# RSL15 register map
Vendor: ONSemiconductor; Series: RSL15 Series; File version: 1.0
onsemi RSL15
CPU: CM33 r0p4, little endian, MPU, FPU, 3 interrupt priority bits
Registers are 32-bit, read-write, reset 0x0 unless marked. A register's access mark holds for its fields unless they carry their own. Offsets are from the block's base; lines under a group give offsets from that group; [hi:lo] are bit positions; {n}, {i} and the like mark numbered series; 'fields as' and 'values as' point back to an identical list; <NAME> marks a mode.

## Memory map
0x1FFFFFFC AHBREGS size 0x4 — AHB registers
0x40000000 SYSCTRL size 0x100 — System Control
0x40000100 CLK size 0x10 — Clock Generation
0x40000200 RESET size 0x4
0x40000300 WATCHDOG size 0x100 — Watchdog Timer
0x40000400 TIMER0 size 0x100 — General-Purpose Timers
0x40000500 TIMER1 size 0x100 — General-Purpose Timers
0x40000600 TIMER2 size 0x100 — General-Purpose Timers
0x40000700 TIMER3 size 0x100 — General-Purpose Timers
0x40000800 FLASH size 0x100 — Flash Interface
0x40000900 GPIO size 0x158 — GPIO Interface and Digital Pad control
0x40000B00 SPI0 size 0x100 — SPI Interface
0x40000C00 SPI1 size 0x100 — SPI Interface
0x40000D00 I2C0 size 0x100 — I2C Interface
0x40000E00 I2C1 size 0x100 — I2C Interface
0x40000F00 UART size 0x100 — UART Interface
0x40001000 PCM size 0x100 — PCM Interface
0x40001100 PWM size 0x100 — PWM Interface
0x40001200 DMA0 size 0x100 — DMA Controller
0x40001300 DMA1 size 0x100 — DMA Controller
0x40001400 DMA2 size 0x100 — DMA Controller
0x40001500 DMA3 size 0x100 — DMA Controller
0x40001600 CRC size 0x100 — CRC Generator Control
0x40001700 ASCC size 0x100
0x40001800 BBIF size 0x100 — Baseband Controller Interface
0x40001900 BB size 0x18C — Baseband Controller
0x40001B00 ACS size 0xA0
0x40001C00 LSAD size 0x100
0x40001D00 SENSOR size 0x74 — Sensor Interface
0x40001E00 TOF size 0x100 — Time Of Flight Timer
0x40002000 LIN size 0x100 — LIN Interface
0x40040800 RF0 size 0x200 — RF Front-End 2.4 GHz
0x40040A00 RF1 size 0x200 — RF Front-End 2.4 GHz
0x40040C00 RF2 size 0x200 — RF Front-End 2.4 GHz
0xE000E004 ICB size 0x4 — Implementation Control Block
0xE000E010 SysTick size 0x10 — SysTick Timer
0xE000E100 NVIC size 0x2043C — Nested Vector Interrupt Controller
0xE000ED00 SCB size 0x90 — System Control Block
0xE000ED90 MPU size 0x34 — Memory Protection Unit
0xE000EDD0 SAU size 0x1C — Security Attribution Unit
0xE000EDF0 DEBUG size 0x1C — Debug Control Block
0xE000EF00 SIG size 0x4 — Software Interrupt Generation
0xE000EF34 FPE size 0x18 — Floating-Point Extension

## AHBREGS — AHB registers
Base 0x1FFFFFFC
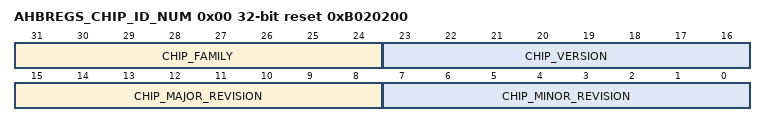
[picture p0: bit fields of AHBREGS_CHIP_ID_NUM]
0x00 AHBREGS_CHIP_ID_NUM ro reset 0xB020200 — Chip ID number
  [31:24] CHIP_FAMILY — Chip Family number
    11=CHIP_FAMILY_NB (BLE family)
  [23:16] CHIP_VERSION — Chip Version number
    2=CHIP_VERSION_NB (Value for Nechako)
  [15:8] CHIP_MAJOR_REVISION — Chip Major Revision number
    2=CHIP_MAJOR_REVISION_NB (Value for Nechako SV2)
  [7:0] CHIP_MINOR_REVISION — Chip Minor Revision number
    0=CHIP_MINOR_REVISION_NB (Value for Nechako SV2)

## CLK — Clock Generation
Base 0x40000100
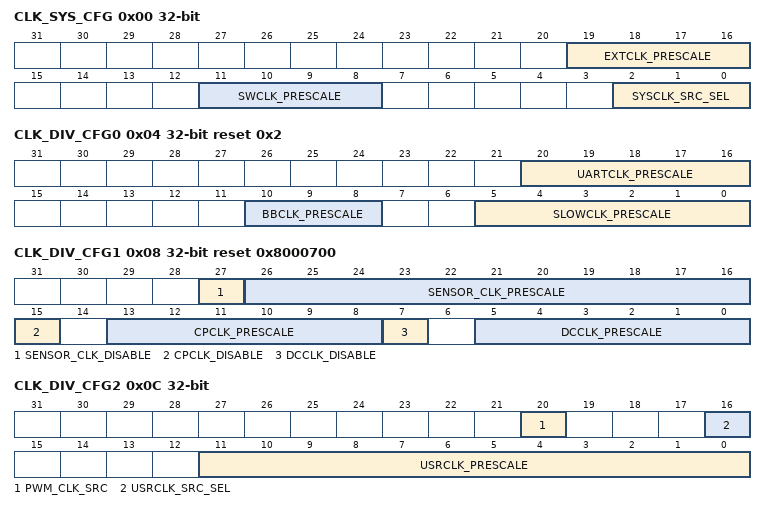
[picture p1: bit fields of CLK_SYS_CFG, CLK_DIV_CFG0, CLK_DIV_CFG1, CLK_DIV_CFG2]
0x00 CLK_SYS_CFG — System Clock Configuration Register
  [19:16] EXTCLK_PRESCALE — Prescale value for the input clock EXTCLK (1 to 16 in steps of 1)
    0=Divide by 1; 1=Divide by 2; 3=Divide by 4; 7=Divide by 8; 14=Divide by 15; 15=Divide by 16
  [11:8] SWCLK_PRESCALE — Prescale value for the input clock from pad SWCLK (1 to 16 in steps of 1)
    values as EXTCLK_PRESCALE
  [2:0] SYSCLK_SRC_SEL — Controls the source of the system clock : SWCLK, RFCLK, RCCLK, or STANDBYCLK
    0=SYSCLK_CLKSRC_RCCLK (Select the RCCLK clock as SYSCLK clock source); 1=SYSCLK_CLKSRC_STANDBYCLK (Select the STANDBYCLK clock as SYSCLK clock source); 2=SYSCLK_CLKSRC_RFCLK (Select the RFCLK clock as SYSCLK clock source); 3=SYSCLK_CLKSRC_SWCLK (Select the SWCLK clock as SYSCLK clock source); 4=SYSCLK_CLKSRC_EXTCLK (Select the EXTCLK clock asSYSCLK clock source)
0x04 CLK_DIV_CFG0 reset 0x2 — Prescale register for SLOWCLK, BBCLK and UARTCLK clocks
  [20:16] UARTCLK_PRESCALE — Prescale value for the UART peripheral clock (1 to 32 in steps of 1)
    0=Divide by 1; 1=Divide by 2; 30=Divide by 31; 31=Divide by 32
  [10:8] BBCLK_PRESCALE — Prescale value for the Baseband peripheral clock (1 to 8 in steps of 1)
    {v}=Divide by {v+1} (v=0..7)
  [5:0] SLOWCLK_PRESCALE — Prescale value for the SLOWCLK clock (1 to 64 in steps of 1)
    {v}=Divide by {v+1} (v=0..3); 5=Divide by 6; 7=Divide by 8; 9=Divide by 10; 11=Divide by 12; 15=Divide by 16; 23=Divide by 24; 47=Divide by 48; 62=Divide by 63; 63=Divide by 64
0x08 CLK_DIV_CFG1 reset 0x8000700 — Prescale register for charge pump clock and sensor clock
  [27] SENSOR_CLK_DISABLE — Sensor clock disable
    0=SENSOR_CLK_ENABLE (Sensor clock enabled); 1=SENSOR_CLK_DISABLE (Sensor clock disabled)
  [26:16] SENSOR_CLK_PRESCALE — Prescale value for the sensor clock
    0=SENSOR_PRESCALE_1 (Divide by 1); 1=SENSOR_PRESCALE_2 (Divide by 2); 2=SENSOR_PRESCALE_3 (Divide by 3); 0x5B8=SENSOR_PRESCALE_1464 (Divide by 1464); 0x5B9=SENSOR_PRESCALE_1465 (Divide by 1465); 0x5BA=SENSOR_PRESCALE_1466 (Divide by 1466); 0x7FD=SENSOR_PRESCALE_2046 (Divide by 2046); 0x7FE=SENSOR_PRESCALE_2047 (Divide by 2047); 0x7FF=SENSOR_PRESCALE_2048 (Divide by 2048)
  [15] CPCLK_DISABLE — Charge pump clock disable
    0=CPCLK_ENABLE (Charge pump clock enabled); 1=CPCLK_DISABLE (Charge pump clock disabled)
  [13:8] CPCLK_PRESCALE — Prescale value for the charge pump clock from the SLOWCLK clock (1 to 64 in steps of 1)
    {v}=Divide by {v+1} (v=0..9); 62=Divide by 63; 63=Divide by 64
  [7] DCCLK_DISABLE — DC-DC converter clock disable
    0=DCCLK_ENABLE (DC-DC converter clock enabled); 1=DCCLK_DISABLE (DC-DC converter clock disabled)
  [5:0] DCCLK_PRESCALE — Prescale value for the DC-DC converter clock (1 to 64 in steps of 1)
    {v}=Divide by {v+1} (v=0..9); 11=Divide by 12; 62=Divide by 63; 63=Divide by 64
0x0C CLK_DIV_CFG2 — Prescale register for User clock
  [20] PWM_CLK_SRC — PWM clock source
    0=PWM_SRC_SYSCLK (PWM clock based on system clock); 1=PWM_SRC_SLOWCLK (PWM clock based on SLOW clock)
  [16] USRCLK_SRC_SEL — USR clock source selection
    0=USRCLK_SRC_SYSCLK (User clock based on system clock); 1=USRCLK_SRC_RFCLK (User clock based on RF clock)
  [11:0] USRCLK_PRESCALE — Prescale value for the USR clock (1 to 4096 in steps of 1)
    0=Divide by 1; 1=Divide by 2; 2=Divide by 3; 0xFFE=Divide by 4095; 0xFFF=Divide by 4096

## Licence text in the file
---------------------------------------------------------------------------- Copyright (c) 2021 Semiconductor Components Industries, LLC (d/b/a onsemi), All Rights Reserved This code is the property of onsemi and may not be redistributed in any form without prior written permission from onsemi. The terms of use and warranty for this code are covered by contractual agreements between onsemi and the licensee. This is Reusable Code. ----------------------------------------------------------------------------
